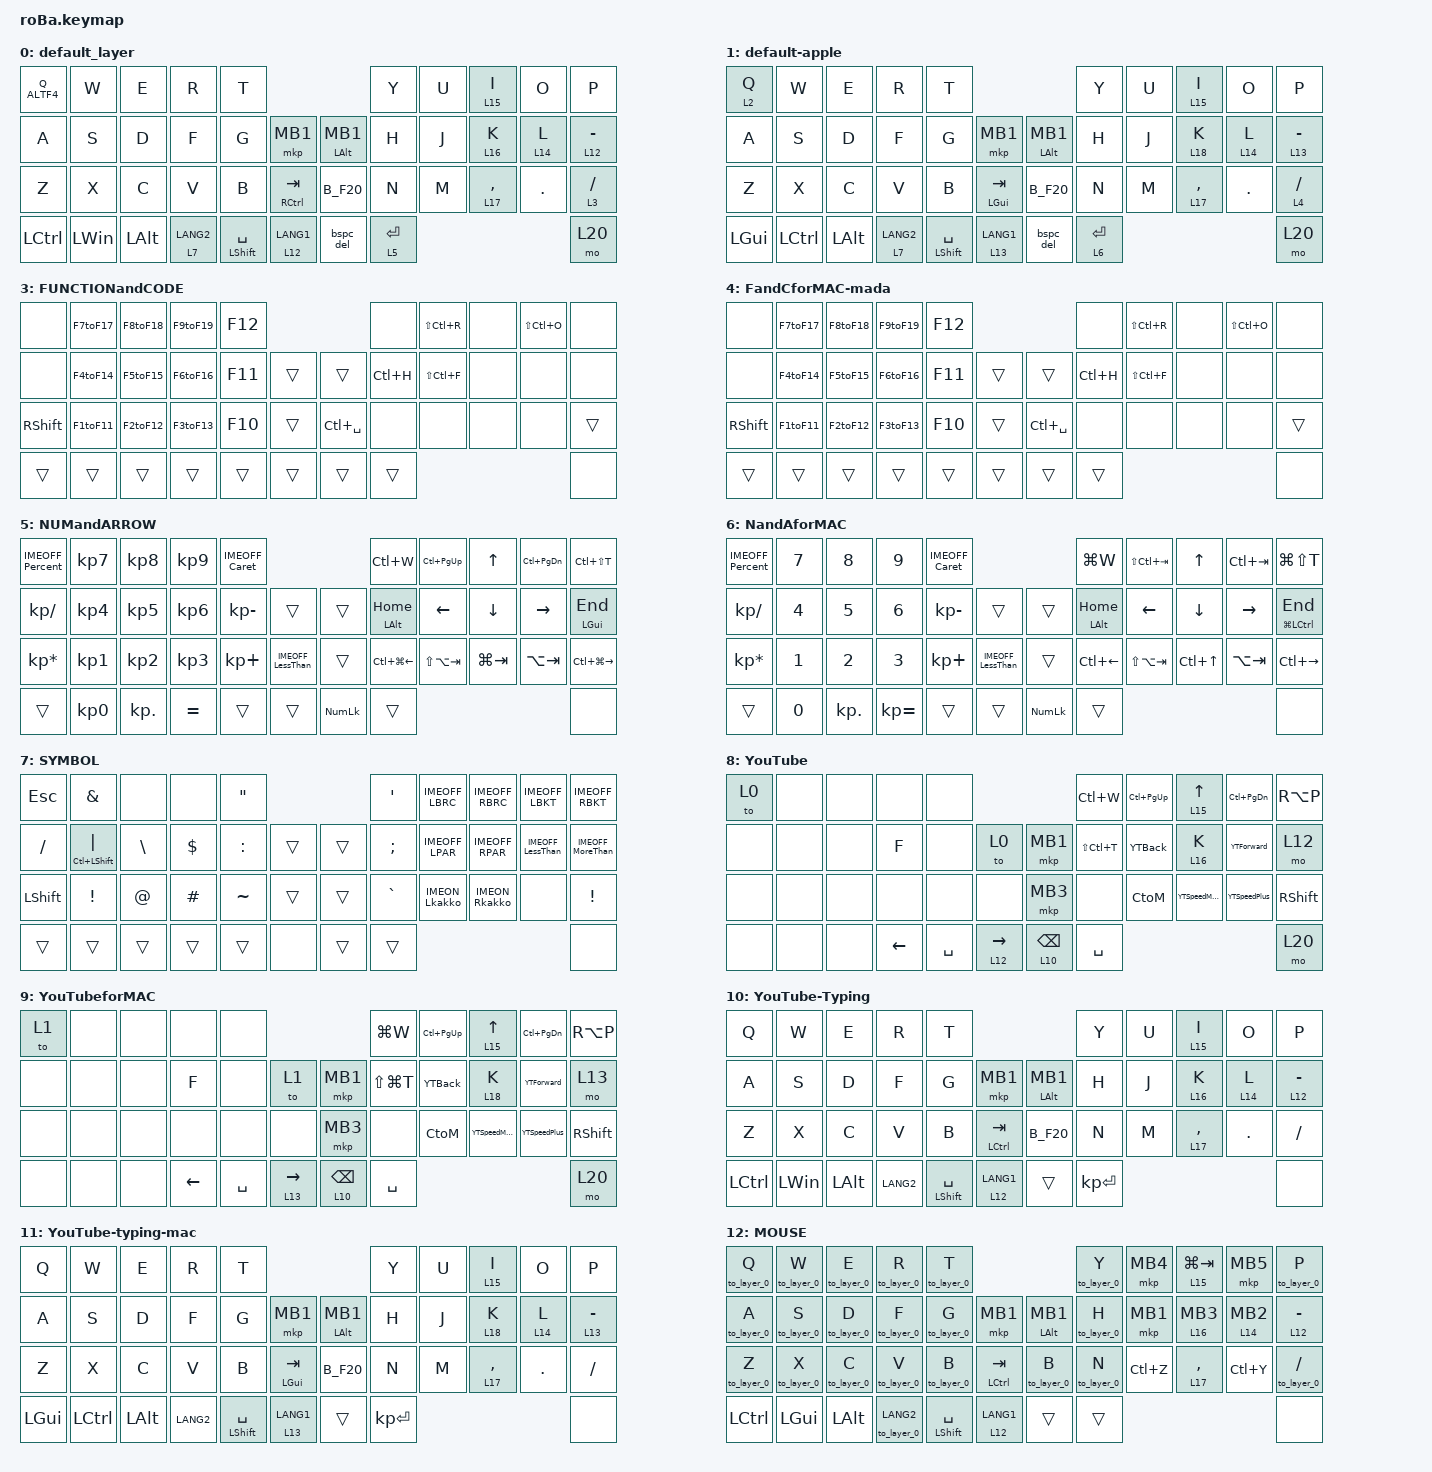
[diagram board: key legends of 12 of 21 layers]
#include <behaviors.dtsi>
#include <dt-bindings/zmk/bt.h>
#include <dt-bindings/zmk/keys.h>
#include <dt-bindings/zmk/outputs.h>
#include <dt-bindings/zmk/pointing.h>

#define ZMK_POINTING_DEFAULT_SCRL_VAL 100

&mt {
    flavor = "balanced";
    quick-tap-ms = <0>;
};

&trackball {
    //automouse-layer = <20>;

    scroll-layers = <15>;
    snipe-layers = <14>;

    arrows_copypaste {
        layers = <16>;
        bindings = <&kp LC(Y)>, <&kp LC(Z)>, <&kp LC(V)>, <&kp LC(C)>;

        tick = <450>;
        wait-ms = <0>;
        tap-ms = <0>;
    };

    arrows_arrows {
        layers = <17>;
        bindings =
            <&kp RIGHT_ARROW>,
            <&kp LEFT_ARROW>,
            <&kp UP_ARROW>,
            <&kp DOWN_ARROW>;

        tick = <10>;
        wait-ms = <0>;
        tap-ms = <5>;
    };

    arrows_copypaste_mac {
        layers = <18>;
        bindings = <&kp LS(LG(Z))>, <&kp LG(Z)>, <&kp LG(V)>, <&kp LG(C)>;

        tick = <450>;
        wait-ms = <0>;
        tap-ms = <0>;
    };
};

/ {
    combos { compatible = "zmk,combos"; };

    macros {
        to_layer_0: to_layer_0 {
            compatible = "zmk,behavior-macro-one-param";
            #binding-cells = <1>;
            bindings = <&to 0 &macro_param_1to1 &kp MACRO_PLACEHOLDER>;
            label = "TO_LAYER_0";
        };

        to_layer_1: to_layer_1 {
            compatible = "zmk,behavior-macro-one-param";
            #binding-cells = <1>;
            bindings = <&to 1 &macro_param_1to1 &kp MACRO_PLACEHOLDER>;
            label = "TO_LAYER_1";
        };

        IMEON_Lkakko: IMEON_kakko {
            compatible = "zmk,behavior-macro";
            #binding-cells = <0>;
            bindings = <&kp LANG1>, <&macro_wait_time 30>, <&kp LEFT_BRACKET>;

            label = "IMEON_KAKKO";
        };

        IMEON_Rkakko: IMEON_Rkakko {
            compatible = "zmk,behavior-macro";
            #binding-cells = <0>;
            bindings = <&kp LANG1>, <&macro_wait_time 30>, <&kp RIGHT_BRACKET>;

            label = "IMEON_RKAKKO";
        };

        IMEOFF_LBKT: IMEOFF_Lkakko {
            compatible = "zmk,behavior-macro";
            #binding-cells = <0>;
            bindings = <&kp LANG2>, <&macro_wait_time 30>, <&kp LEFT_BRACKET>;

            label = "IMEOFF_LKAKKO";
        };

        IMEOFF_RBKT: IMEOFF_Rkakko {
            compatible = "zmk,behavior-macro";
            #binding-cells = <0>;
            bindings = <&kp LANG2>, <&macro_wait_time 30>, <&kp RIGHT_BRACKET>;

            label = "IMEOFF_RKAKKO";
        };

        IMEOFF_LPAR: IMEOFF_LPAR {
            compatible = "zmk,behavior-macro";
            #binding-cells = <0>;
            bindings = <&kp LANG2>, <&macro_wait_time 30>, <&kp LPAR>;

            label = "IMEOFF_LPAR";
        };

        IMEOFF_RPAR: IMEOFF_RPAR {
            compatible = "zmk,behavior-macro";
            #binding-cells = <0>;
            bindings = <&kp LANG2>, <&macro_wait_time 30>, <&kp RPAR>;

            label = "IMEOFF_RPAR";
        };

        IMEOFF_LBRC: IMEOFF_LBRC {
            compatible = "zmk,behavior-macro";
            #binding-cells = <0>;
            bindings = <&kp LANG2>, <&macro_wait_time 30>, <&kp LBRC>;

            label = "IMEOFF_LBRC";
        };

        IMEOFF_RBRC: IMEOFF_RBRC {
            compatible = "zmk,behavior-macro";
            #binding-cells = <0>;
            bindings = <&kp LANG2>, <&macro_wait_time 30>, <&kp RBRC>;

            label = "IMEOFF_RBRC";
        };

        IMEOFF_LessThan: IMEOFF_LessThan {
            compatible = "zmk,behavior-macro";
            #binding-cells = <0>;
            bindings = <&kp LANG2>, <&macro_wait_time 30>, <&kp LESS_THAN>;

            label = "IMEOFF_LESSTHAN";
        };

        IMEOFF_Percent: IMEOFF_Percent {
            compatible = "zmk,behavior-macro";
            #binding-cells = <0>;
            bindings = <&kp LANG2>, <&macro_wait_time 30>, <&kp PERCENT>;

            label = "IMEOFF_PERCENT";
        };

        IMEOFF_Caret: IMEOFF_Caret {
            compatible = "zmk,behavior-macro";
            #binding-cells = <0>;
            bindings = <&kp LANG2>, <&macro_wait_time 30>, <&kp CARET>;

            label = "IMEOFF_CARET";
        };

        IMEOFF_MoreThan: IMEOFF_MoreThan {
            compatible = "zmk,behavior-macro";
            #binding-cells = <0>;
            bindings = <&kp LANG2>, <&macro_wait_time 30>, <&kp GREATER_THAN>;

            label = "IMEOFF_MORETHAN";
        };

        Windows1: Windows1 {
            compatible = "zmk,behavior-macro";
            #binding-cells = <0>;
            bindings = <&bt BT_SEL 0 &to 0>;
            label = "WINDOWS1";
        };

        MacOS: MacOS {
            compatible = "zmk,behavior-macro";
            #binding-cells = <0>;
            bindings = <&bt BT_SEL 1 &to 1>;
            label = "MACOS";
        };

        iPhone: iPhone {
            compatible = "zmk,behavior-macro";
            #binding-cells = <0>;
            bindings = <&bt BT_SEL 2 &to 1>;
            label = "IPHONE";
        };

        iPad: iPad {
            compatible = "zmk,behavior-macro";
            #binding-cells = <0>;
            bindings = <&bt BT_SEL 3 &to 1>;
            label = "IPAD";
        };

        Windows2: Windows2 {
            compatible = "zmk,behavior-macro";
            #binding-cells = <0>;
            bindings = <&bt BT_SEL 4 &to 0>;
            label = "WINDOWS2";
        };
    };

    behaviors {
        lt_to_layer_0: lt_to_layer_0 {
            compatible = "zmk,behavior-hold-tap";
            label = "LAYER_TAP_TO_0";
            bindings = <&mo>, <&to_layer_0>;

            #binding-cells = <2>;
            tapping-term-ms = <200>;
        };

        lt_to_layer_1: lt_to_layer_1 {
            compatible = "zmk,behavior-hold-tap";
            label = "LAYER_TAP_TO_1";
            bindings = <&mo>, <&to_layer_1>;

            #binding-cells = <2>;
            tapping-term-ms = <200>;
        };

        YTMute: YTMute {
            compatible = "zmk,behavior-mod-morph";
            label = "YTMUTE";
            bindings = <&kp DOWN_ARROW>, <&kp M>;

            #binding-cells = <0>;
            mods = <(MOD_RSFT)>;
        };

        YTSpeedMinus: YTSpeedMinus {
            compatible = "zmk,behavior-mod-morph";
            label = "YTSPEEDMINUS";
            bindings = <&kp LA(COMMA)>, <&kp COMMA>;

            #binding-cells = <0>;
            mods = <(MOD_RSFT)>;
        };

        YTSpeedPlus: YTSpeedPlus {
            compatible = "zmk,behavior-mod-morph";
            label = "YTSPEEDPLUS";
            bindings = <&kp RA(PERIOD)>, <&kp PERIOD>;

            #binding-cells = <0>;
            mods = <(MOD_RSFT)>;
        };

        YTBack: YTBack {
            compatible = "zmk,behavior-mod-morph";
            label = "YTBACK";
            bindings = <&kp LEFT_ARROW>, <&kp J>;

            #binding-cells = <0>;
            mods = <(MOD_RSFT)>;
        };

        YTForward: YTForward {
            compatible = "zmk,behavior-mod-morph";
            label = "YTFORWARD";
            bindings = <&kp RIGHT_ARROW>, <&kp L>;

            #binding-cells = <0>;
            mods = <(MOD_RSFT)>;
        };

        F1toF11: F1toF11 {
            compatible = "zmk,behavior-mod-morph";
            label = "F1TOF11";
            bindings = <&kp F1>, <&kp F11>;

            #binding-cells = <0>;
            mods = <(MOD_RSFT)>;
        };

        F2toF12: F2toF12 {
            compatible = "zmk,behavior-mod-morph";
            label = "F2TOF12";
            bindings = <&kp F2>, <&kp F12>;

            #binding-cells = <0>;
            mods = <(MOD_RSFT)>;
        };

        F3toF13: F3toF13 {
            compatible = "zmk,behavior-mod-morph";
            label = "F3TOF13";
            bindings = <&kp F3>, <&kp F13>;

            #binding-cells = <0>;
            mods = <(MOD_RSFT)>;
        };

        F4toF14: F4toF14 {
            compatible = "zmk,behavior-mod-morph";
            label = "F4TOF14";
            bindings = <&kp F4>, <&kp F14>;

            #binding-cells = <0>;
            mods = <(MOD_RSFT)>;
        };

        F5toF15: F5toF15 {
            compatible = "zmk,behavior-mod-morph";
            label = "F5TOF15";
            bindings = <&kp F5>, <&kp F15>;

            #binding-cells = <0>;
            mods = <(MOD_RSFT)>;
        };

        F6toF16: F6toF16 {
            compatible = "zmk,behavior-mod-morph";
            label = "F6TOF16";
            bindings = <&kp F6>, <&kp F16>;

            #binding-cells = <0>;
            mods = <(MOD_RSFT)>;
        };

        F7toF17: F7toF17 {
            compatible = "zmk,behavior-mod-morph";
            label = "F7TOF17";
            bindings = <&kp F7>, <&kp F17>;

            #binding-cells = <0>;
            mods = <(MOD_RSFT)>;
        };

        F8toF18: F8toF18 {
            compatible = "zmk,behavior-mod-morph";
            label = "F8TOF18";
            bindings = <&kp F8>, <&kp F18>;

            #binding-cells = <0>;
            mods = <(MOD_RSFT)>;
        };

        F9toF19: F9toF19 {
            compatible = "zmk,behavior-mod-morph";
            label = "F9TOF19";
            bindings = <&kp F9>, <&kp F19>;

            #binding-cells = <0>;
            mods = <(MOD_RSFT)>;
        };

        bspc_del: backspace_delete {
            compatible = "zmk,behavior-mod-morph";
            #binding-cells = <0>;
            bindings = <&kp BACKSPACE>, <&kp DELETE>;

            mods = <MOD_LSFT>;
        };

        bspc_mo: backspace_or_layer {
            compatible = "zmk,behavior-hold-tap";
            #binding-cells = <2>;
            tapping-term-ms = <200>;
            flavor = "tap-preferred";
            bindings = <&mo>, <&bspc_del>;
        };

        mb_mo: mb_or_layer {
            compatible = "zmk,behavior-hold-tap";
            #binding-cells = <2>;
            tapping-term-ms = <200>;
            flavor = "tap-preferred";
            bindings = <&mo>, <&mkp>;
        };

        scroll_up_down: behavior_sensor_rotate_mouse_wheel_up_down {
            compatible = "zmk,behavior-sensor-rotate";
            label = "ENCODER_MSC_DOWN_UP";
            #sensor-binding-cells = <0>;
            bindings = <&msc SCRL_DOWN>, <&msc SCRL_UP>;

            tap-ms = <20>;
        };

        B_F20: B_F20 {
            compatible = "zmk,behavior-mod-morph";
            label = "B_F20";
            bindings = <&kp B>, <&kp F20>;

            #binding-cells = <0>;
            mods = <(MOD_LSFT)>;
        };

        kp_mkp: kp_mkp {
            compatible = "zmk,behavior-hold-tap";
            label = "KP_MKP";
            #binding-cells = <2>;
            tapping-term-ms = <200>;
            bindings = <&kp>, <&mkp>;
        };

        lt_YTMute: lt_YTMute {
            compatible = "zmk,behavior-hold-tap";
            label = "LT_YTMUTE";
            bindings = <&lt>, <&YTMute>;

            #binding-cells = <2>;
            tapping-term-ms = <200>;
        };

        CtoM: CtoM {
            compatible = "zmk,behavior-mod-morph";
            label = "CTOM";
            bindings = <&kp C>, <&kp M>;

            #binding-cells = <0>;
            mods = <(MOD_RSFT)>;
        };

        Q_ALTF4: Q_ALTF4 {
            compatible = "zmk,behavior-mod-morph";
            label = "Q_ALTF4";
            bindings = <&kp Q>, <&kp LA(F4)>;

            #binding-cells = <0>;
            mods = <(MOD_RCTL)>;
        };
    };

    keymap {
        compatible = "zmk,keymap";

        default_layer {
            bindings = <
&Q_ALTF4   &kp W         &kp E         &kp R        &kp T                                                      &kp Y        &kp U  &lt 15 I      &kp O     &kp P
&kp A      &kp S         &kp D         &kp F        &kp G                 &mkp MB1           &kp_mkp LALT MB1  &kp H        &kp J  &lt 16 K      &lt 14 L  &lt 12 MINUS
&kp Z      &kp X         &kp C         &kp V        &kp B                 &mt RCTRL TAB      &B_F20            &kp N        &kp M  &lt 17 COMMA  &kp DOT   &lt 3 SLASH
&kp LCTRL  &kp LEFT_WIN  &kp LEFT_ALT  &lt 7 LANG2  &mt LEFT_SHIFT SPACE  &lt 12 LANG1       &bspc_del         &lt 5 ENTER                                 &mo 20
            >;

            sensor-bindings = <&scroll_up_down>;
        };

        default-apple {
            bindings = <
&lt 2 Q   &kp W      &kp E         &kp R        &kp T                                                     &kp Y        &kp U  &lt 15 I      &kp O     &kp P
&kp A     &kp S      &kp D         &kp F        &kp G                 &mkp MB1          &kp_mkp LALT MB1  &kp H        &kp J  &lt 18 K      &lt 14 L  &lt 13 MINUS
&kp Z     &kp X      &kp C         &kp V        &kp B                 &mt LGUI TAB      &B_F20            &kp N        &kp M  &lt 17 COMMA  &kp DOT   &lt 4 SLASH
&kp LGUI  &kp LCTRL  &kp LEFT_ALT  &lt 7 LANG2  &mt LEFT_SHIFT SPACE  &lt 13 LANG1      &bspc_del         &lt 6 ENTER                                 &mo 20
            >;

            sensor-bindings = <&scroll_up_down>;
        };

        APPLE {
            bindings = <
&none  &none  &none  &none  &none                           &kp LG(NUMBER_1)  &kp LG(LA(UP_ARROW))        &kp LA(LC(LG(NUMBER_2)))  &kp LG(LA(RIGHT_ARROW))      &none
&none  &none  &none  &none  &none  &none      &kp GLOBE     &kp LG(NUMBER_2)  &kp LG(LA(LC(LEFT_ARROW)))  &kp LG(LC(F))             &kp LG(LA(LC(RIGHT_ARROW)))  &none
&none  &none  &none  &none  &none  &none      &kp UP_ARROW  &kp LG(NUMBER_3)  &kp LG(LA(LEFT_ARROW))      &kp LA(LC(LG(NUMBER_4)))  &kp LG(LA(DOWN_ARROW))       &none
&none  &none  &none  &none  &none  &none      &none         &none                                                                                                &none
            >;

            sensor-bindings = <&scroll_up_down>;
        };

        FUNCTIONandCODE {
            bindings = <
&none      &F7toF17  &F8toF18  &F9toF19  &kp F12                             &none      &kp LS(LC(R))  &none  &kp LS(LC(O))  &none
&none      &F4toF14  &F5toF15  &F6toF16  &kp F11  &trans      &trans         &kp LC(H)  &kp LS(LC(F))  &none  &none          &none
&kp RSHFT  &F1toF11  &F2toF12  &F3toF13  &kp F10  &trans      &kp LC(SPACE)  &none      &none          &none  &none          &trans
&trans     &trans    &trans    &trans    &trans   &trans      &trans         &trans                                          &none
            >;

            sensor-bindings = <&scroll_up_down>;
        };

        FandCforMAC-mada {
            bindings = <
&none      &F7toF17  &F8toF18  &F9toF19  &kp F12                             &none      &kp LS(LC(R))  &none  &kp LS(LC(O))  &none
&none      &F4toF14  &F5toF15  &F6toF16  &kp F11  &trans      &trans         &kp LC(H)  &kp LS(LC(F))  &none  &none          &none
&kp RSHFT  &F1toF11  &F2toF12  &F3toF13  &kp F10  &trans      &kp LC(SPACE)  &none      &none          &none  &none          &trans
&trans     &trans    &trans    &trans    &trans   &trans      &trans         &trans                                          &none
            >;

            sensor-bindings = <&scroll_up_down>;
        };

        NUMandARROW {
            bindings = <
&IMEOFF_Percent  &kp KP_NUMBER_7  &kp KP_NUMBER_8  &kp KP_NUMBER_9  &IMEOFF_Caret                                        &kp LC(W)               &kp LC(PG_UP)    &kp UP_ARROW    &kp LC(PG_DN)  &kp LC(LS(T))
&kp KP_SLASH     &kp KP_NUMBER_4  &kp KP_NUMBER_5  &kp KP_NUMBER_6  &kp KP_MINUS   &trans                &trans          &mt LALT HOME           &kp LEFT_ARROW   &kp DOWN_ARROW  &kp RIGHT      &mt LGUI END
&kp KP_ASTERISK  &kp KP_NUMBER_1  &kp KP_NUMBER_2  &kp KP_NUMBER_3  &kp KP_PLUS    &IMEOFF_LessThan      &trans          &kp LC(LG(LEFT_ARROW))  &kp LS(LA(TAB))  &kp LG(TAB)     &kp LA(TAB)    &kp LC(LG(RIGHT_ARROW))
&trans           &kp KP_N0        &kp KP_DOT       &kp EQUAL        &trans         &trans                &kp KP_NUMLOCK  &trans                                                                  &none
            >;

            sensor-bindings = <&inc_dec_kp PG_UP PG_DN>;
        };

        NandAforMAC {
            bindings = <
&IMEOFF_Percent  &kp N7        &kp N8        &kp N9        &IMEOFF_Caret                                        &kp LG(W)           &kp LS(LC(TAB))  &kp UP_ARROW      &kp LC(TAB)      &kp LG(LS(T))
&kp KP_SLASH     &kp NUMBER_4  &kp N5        &kp NUMBER_6  &kp KP_MINUS   &trans                &trans          &mt LALT HOME       &kp LEFT_ARROW   &kp DOWN_ARROW    &kp RIGHT_ARROW  &mt LG(LCTRL) END
&kp KP_ASTERISK  &kp NUMBER_1  &kp NUMBER_2  &kp NUMBER_3  &kp KP_PLUS    &IMEOFF_LessThan      &trans          &kp LC(LEFT_ARROW)  &kp LS(LA(TAB))  &kp LC(UP_ARROW)  &kp LA(TAB)      &kp LC(RIGHT_ARROW)
&trans           &kp N0        &kp KP_DOT    &kp KP_EQUAL  &trans         &trans                &kp KP_NUMLOCK  &trans                                                                  &none
            >;

            sensor-bindings = <&inc_dec_kp PG_UP PG_DN>;
        };

        SYMBOL {
            bindings = <
&kp ESC    &kp AMPERSAND       &none          &none       &kp DOUBLE_QUOTES                      &kp SQT        &IMEOFF_LBRC   &IMEOFF_RBRC   &IMEOFF_LBKT      &IMEOFF_RBKT
&kp SLASH  &mt LC(LSHFT) PIPE  &kp BACKSLASH  &kp DOLLAR  &kp COLON          &trans      &trans  &kp SEMICOLON  &IMEOFF_LPAR   &IMEOFF_RPAR   &IMEOFF_LessThan  &IMEOFF_MoreThan
&kp LSHFT  &kp EXCLAMATION     &kp AT_SIGN    &kp HASH    &kp TILDE          &trans      &trans  &kp GRAVE      &IMEON_Lkakko  &IMEON_Rkakko  &none             &kp EXCL
&trans     &trans              &trans         &trans      &trans             &none       &trans  &trans                                                         &none
            >;

            sensor-bindings = <&scroll_up_down>;
        };

        YouTube {
            bindings = <
&to 0  &none  &none  &none           &none                                                &kp LC(W)      &kp LC(PG_UP)  &lt 15 UP_ARROW  &kp LC(PAGE_DOWN)  &kp RA(P)
&none  &none  &none  &kp F           &none      &to 0                   &mkp MB1          &kp LS(LC(T))  &YTBack        &lt 16 K         &YTForward         &mo 12
&none  &none  &none  &none           &none      &none                   &mkp MB3          &none          &CtoM          &YTSpeedMinus    &YTSpeedPlus       &kp RSHFT
&none  &none  &none  &kp LEFT_ARROW  &kp SPACE  &lt 12 RIGHT_ARROW      &lt 10 BACKSPACE  &kp SPACE                                                         &mo 20
            >;

            sensor-bindings = <&scroll_up_down>;
        };

        YouTubeforMAC {
            bindings = <
&to 1  &none  &none  &none           &none                                                &kp LG(W)      &kp LC(PG_UP)  &lt 15 UP_ARROW  &kp LC(PAGE_DOWN)  &kp RA(P)
&none  &none  &none  &kp F           &none      &to 1                   &mkp MB1          &kp LS(LG(T))  &YTBack        &lt 18 K         &YTForward         &mo 13
&none  &none  &none  &none           &none      &none                   &mkp MB3          &none          &CtoM          &YTSpeedMinus    &YTSpeedPlus       &kp RSHFT
&none  &none  &none  &kp LEFT_ARROW  &kp SPACE  &lt 13 RIGHT_ARROW      &lt 10 BACKSPACE  &kp SPACE                                                         &mo 20
            >;

            sensor-bindings = <&scroll_up_down>;
        };

        YouTube-Typing {
            bindings = <
&kp Q      &kp W         &kp E         &kp R      &kp T                                                      &kp Y         &kp U  &lt 15 I      &kp O     &kp P
&kp A      &kp S         &kp D         &kp F      &kp G                 &mkp MB1           &kp_mkp LALT MB1  &kp H         &kp J  &lt 16 K      &lt 14 L  &lt 12 MINUS
&kp Z      &kp X         &kp C         &kp V      &kp B                 &mt LCTRL TAB      &B_F20            &kp N         &kp M  &lt 17 COMMA  &kp DOT   &kp SLASH
&kp LCTRL  &kp LEFT_WIN  &kp LEFT_ALT  &kp LANG2  &mt LEFT_SHIFT SPACE  &lt 12 LANG1       &trans            &kp KP_ENTER                                 &none
            >;

            sensor-bindings = <&scroll_up_down>;
        };

        YouTube-typing-mac {
            bindings = <
&kp Q     &kp W      &kp E         &kp R      &kp T                                                     &kp Y         &kp U  &lt 15 I      &kp O     &kp P
&kp A     &kp S      &kp D         &kp F      &kp G                 &mkp MB1          &kp_mkp LALT MB1  &kp H         &kp J  &lt 18 K      &lt 14 L  &lt 13 MINUS
&kp Z     &kp X      &kp C         &kp V      &kp B                 &mt LGUI TAB      &B_F20            &kp N         &kp M  &lt 17 COMMA  &kp DOT   &kp SLASH
&kp LGUI  &kp LCTRL  &kp LEFT_ALT  &kp LANG2  &mt LEFT_SHIFT SPACE  &lt 13 LANG1      &trans            &kp KP_ENTER                                 &none
            >;

            sensor-bindings = <&scroll_up_down>;
        };

        MOUSE {
            bindings = <
&to_layer_0 Q  &to_layer_0 W  &to_layer_0 E  &to_layer_0 R      &to_layer_0 T                                                   &to_layer_0 Y  &mkp MB4   &lt 15 LG(TAB)  &mkp MB5       &to_layer_0 P
&to_layer_0 A  &to_layer_0 S  &to_layer_0 D  &to_layer_0 F      &to_layer_0 G    &mkp MB1                     &kp_mkp LALT MB1  &to_layer_0 H  &mkp MB1   &mb_mo 16 MB3   &mb_mo 14 MB2  &lt_to_layer_0 12 MINUS
&to_layer_0 Z  &to_layer_0 X  &to_layer_0 C  &to_layer_0 V      &to_layer_0 B    &mt LCTRL TAB                &to_layer_0 B     &to_layer_0 N  &kp LC(Z)  &lt 17 COMMA    &kp LC(Y)      &to_layer_0 SLASH
&kp LCTRL      &kp LGUI       &kp LALT       &to_layer_0 LANG2  &mt LSHFT SPACE  &lt_to_layer_0 12 LANG1      &trans            &trans                                                   &none
            >;

            sensor-bindings = <&scroll_up_down>;
        };

        mouse-mac {
            bindings = <
&to_layer_1 Q  &to_layer_1 W  &to_layer_1 E  &to_layer_1 R      &to_layer_1 T                                                    &to_layer_1 Y  &kp LG(LBKT)  &lt 15 LC(UP_ARROW)  &kp LG(RBKT)   &to_layer_1 P
&to_layer_1 A  &to_layer_1 S  &to_layer_1 D  &to_layer_1 F      &to_layer_1 G     &mkp MB1                     &kp_mkp LALT MB1  &to_layer_1 H  &mkp MB1      &mb_mo 18 MB3        &mb_mo 14 MB2  &lt_to_layer_1 13 MINUS
&to_layer_1 Z  &to_layer_1 X  &to_layer_1 C  &to_layer_1 V      &to_layer_1 B     &mt LGUI TAB                 &to_layer_1 B     &to_layer_1 N  &kp LG(Z)     &lt 17 COMMA         &kp LS(LG(Z))  &to_layer_1 SLASH
&kp LGUI       &kp LCTRL      &kp LALT       &to_layer_1 LANG2  &mt LSHIFT SPACE  &lt_to_layer_1 13 LANG1      &trans            &trans                                                           &none
            >;

            sensor-bindings = <&scroll_up_down>;
        };

        MOUSE_SLOW {
            bindings = <
&trans  &trans  &trans  &trans  &trans                      &trans  &trans    &mo 15  &trans  &trans
&trans  &trans  &trans  &trans  &trans  &trans      &trans  &trans  &mkp MB1  &trans  &trans  &trans
&trans  &trans  &trans  &trans  &trans  &trans      &trans  &trans  &trans    &trans  &trans  &trans
&trans  &trans  &trans  &trans  &trans  &trans      &trans  &trans                            &trans
            >;

            sensor-bindings = <&scroll_up_down>;
        };

        SCROLL {
            bindings = <
&trans  &trans  &trans  &trans  &trans                      &trans  &trans    &trans  &trans  &trans
&trans  &trans  &trans  &trans  &trans  &trans      &trans  &trans  &mkp MB1  &trans  &trans  &trans
&trans  &trans  &trans  &trans  &trans  &trans      &trans  &trans  &trans    &trans  &trans  &trans
&trans  &trans  &trans  &trans  &trans  &trans      &trans  &trans                            &trans
            >;

            sensor-bindings = <&scroll_up_down>;
        };

        GESTURE {
            bindings = <
&trans  &trans  &trans  &trans  &trans                      &trans  &trans  &trans  &trans  &trans
&trans  &trans  &trans  &trans  &trans  &trans      &trans  &trans  &trans  &trans  &trans  &trans
&trans  &trans  &trans  &trans  &trans  &trans      &trans  &trans  &trans  &trans  &trans  &trans
&trans  &trans  &trans  &trans  &trans  &trans      &trans  &trans                          &trans
            >;

            sensor-bindings = <&scroll_up_down>;
        };

        GESTURE2 {
            bindings = <
&trans  &trans  &trans  &trans  &trans                      &trans  &trans  &trans  &trans  &trans
&trans  &trans  &trans  &trans  &trans  &trans      &trans  &trans  &trans  &trans  &trans  &trans
&trans  &trans  &trans  &trans  &trans  &trans      &trans  &trans  &trans  &trans  &trans  &trans
&trans  &trans  &trans  &trans  &trans  &trans      &trans  &trans                          &trans
            >;

            sensor-bindings = <&scroll_up_down>;
        };

        GESTURE_MAC {
            bindings = <
&trans  &trans  &trans  &trans  &trans                      &trans  &trans  &trans  &trans  &trans
&trans  &trans  &trans  &trans  &trans  &trans      &trans  &trans  &trans  &trans  &trans  &trans
&trans  &trans  &trans  &trans  &trans  &trans      &trans  &trans  &trans  &trans  &trans  &trans
&trans  &trans  &trans  &trans  &trans  &trans      &trans  &trans                          &trans
            >;

            sensor-bindings = <&scroll_up_down>;
        };

        LogicPro {
            bindings = <
&trans  &trans  &trans  &trans  &trans                      &trans  &trans  &trans  &trans  &trans
&trans  &trans  &trans  &trans  &trans  &to 1       &trans  &trans  &trans  &trans  &trans  &trans
&trans  &trans  &trans  &trans  &trans  &trans      &trans  &trans  &trans  &trans  &trans  &trans
&trans  &trans  &trans  &trans  &trans  &trans      &trans  &trans                          &trans
            >;

            sensor-bindings = <&scroll_up_down>;
        };

        Bluetooth {
            bindings = <
&Windows1     &MacOS        &iPhone       &iPad         &Windows2                                  &none  &kp LS(LA(LC(LG(O))))  &kp LA(LC(LG(O)))  &kp LA(LC(LG(P)))  &kp PRINTSCREEN
&to 0         &to 1         &out OUT_TOG  &none         &none         &sys_reset      &bootloader  &none  &none                  &none              &to 19             &to 9
&bt BT_SEL 0  &bt BT_SEL 1  &bt BT_SEL 2  &bt BT_SEL 3  &bt BT_SEL 4  &bt BT_CLR      &none        &none  &kp LG(LA(K))          &none              &to 0              &to 8
&none         &none         &none         &none         &none         &none           &none        &none                                                               &trans
            >;
        };
    };
};
